AUTOSAR XML (schema 4-2-2)
package /VectorAutosarExplorerGeneratedObjects/SYSTEM
  system System
package /VectorAutosarExplorerGeneratedObjects/Induction_Training_BB
  can cluster Induction_Training_BB: baudrate=500000, protocol-name=CAN, speed=250000
    can physical channel CAR_BackBone: comm-connectors=[Connector_eJAD_AC_ECU_5f730b4d60fd8937, Connector_Car_Network_695cc9c2051648f8]
      frame AmbTempOutCar: id 0x1A7, from Car_Network, to eJAD_AC_ECU, frame-length=12, can-addressing-mode=STANDARD, can-frame-tx-behavior=CAN-20
        pdu AmbTempOutCar_PDU: length=8
          signal AmbTempOutCar_PDU_Signal: start 0, 12 bit, little-endian, system signal AmbTempOutCar_PDU_Signal_e8e9817b538522da, data-type-policy=OVERRIDE, base-type=New_BaseType, compu {phys=raw*0.1-127.5 for raw -127.5..126.5}, to eJAD_AC_ECU
      frame AmbTempInCar: id 0x242, from Car_Network, to eJAD_AC_ECU, frame-length=8, can-addressing-mode=STANDARD, can-frame-tx-behavior=CAN-20
        pdu AmbTempInCar_PDU: length=8
          signal AmbTempInCar_PDU_Signal: start 10, 12 bit, little-endian, system signal AmbTempInCar_PDU_Signal_d38db15a12d99ae0, data-type-policy=OVERRIDE, base-type=New_BaseType_1, compu {phys=raw*0.1-127.5 for raw -127.5..126.5}, to eJAD_AC_ECU
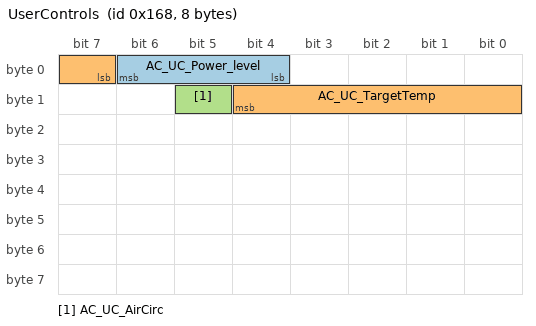
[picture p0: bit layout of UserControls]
      frame UserControls: id 0x168, from Car_Network, to eJAD_AC_ECU, frame-length=8, can-addressing-mode=STANDARD, can-frame-tx-behavior=CAN-20
        pdu UserControls_PDU: length=8
          signal AC_UC_Power_level: start 4, 3 bit, little-endian, system signal AC_UC_Power_level_a94e1a11ca90d4ce, data-type-policy=OVERRIDE, base-type=New_BaseType_2, compu {0=AC_UNIT_OFF, 1..4=AC_UNIT_PL1..AC_UNIT_PL4, 5=AC_UNIT_MAX}, to eJAD_AC_ECU
          signal AC_UC_TargetTemp: start 7, 6 bit, little-endian, system signal AC_UC_TargetTemp_525caf780043ccd2, data-type-policy=OVERRIDE, base-type=New_BaseType_2, compu {phys=raw for raw 18..33}, to eJAD_AC_ECU
          signal AC_UC_AirCirc: start 13, 1 bit, little-endian, system signal AC_UC_AirCirc_4982379d745170f0, data-type-policy=OVERRIDE, base-type=New_BaseType_2, compu {phys=raw for raw 0..1}, to eJAD_AC_ECU
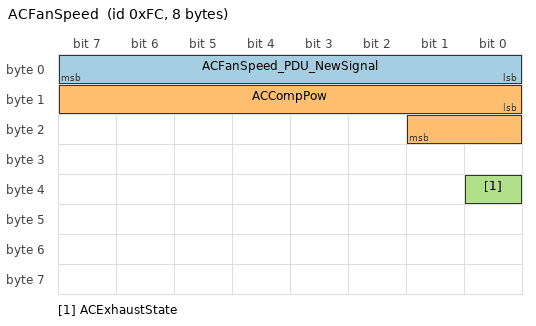
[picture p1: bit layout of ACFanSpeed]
      frame ACFanSpeed: id 0xFC, from eJAD_AC_ECU, to Car_Network, frame-length=8, can-addressing-mode=STANDARD, can-frame-tx-behavior=CAN-20
        pdu ACFanSpeed_PDU: length=8
          signal ACFanSpeed_PDU_NewSignal: start 0, 8 bit, little-endian, system signal ACFanSpeed_PDU_NewSignal_fc7b1c6d9e92d4ff, data-type-policy=OVERRIDE, base-type=New_BaseType, to Car_Network
          signal ACCompPow: start 8, 10 bit, little-endian, system signal ACCompPow_274b307919b78395, data-type-policy=OVERRIDE, base-type=New_BaseType, compu {phys=raw for raw 0..750}, to Car_Network
          signal ACExhaustState: start 32, 1 bit, little-endian, system signal ACExhaustState_7fbac8b577bd68fd, data-type-policy=OVERRIDE, base-type=New_BaseType, to Car_Network
package /VectorAutosarExplorerGeneratedObjects/ECU_INSTANCES
  ecu instance eJAD_AC_ECU: associated-com-i-pdu-group=[PduGroup_6f1441ac0ffe40b4a12c41c00adac4bd_Rx, PduGroup_b6fddf9f996e4f7a947d8b87f8da3fb2_Rx, PduGroup_df39a3b4272b424f80ca0a1ab2d3ac62_Rx, PduGroup_c82bbc8115c7464b87dc9baec7e90fcb_Tx, PduGroup_ff9273c8d3e04add9b1da927b56ab3f5_Tx], diagnostic-address=0
    can communication controller Controller_eJAD_AC_ECU_7f252cc98424769f: can-controller-attributes=can-controller-configuration={time-seg-1=15, time-seg-2=15}
    can communication controller Controller_eJAD_AC_ECU_5f3c2b4b33700a26
    can communication connector Connector_eJAD_AC_ECU_5f730b4d60fd8937: comm-controller=Controller_eJAD_AC_ECU_7f252cc98424769f
    can communication connector Connector_eJAD_AC_ECU_6d360ae10a108b45: comm-controller=Controller_eJAD_AC_ECU_5f3c2b4b33700a26
  ecu instance ExternalTester: associated-com-i-pdu-group=PduGroup_5b4b45473c864a7aaadf3ae2082b22b3_Rx, diagnostic-address=0
    can communication controller Controller_ExternalTester_4f982107dc28de72
    can communication connector Connector_ExternalTester_6d8a6f9d0db8a12c: comm-controller=Controller_ExternalTester_4f982107dc28de72
  ecu instance Car_Network: associated-com-i-pdu-group=[PduGroup_8e237c9982f64dca92b43b8216140bb0_Tx, PduGroup_b78d3610b2834c2f94fc1fb22db2b92b_Tx, PduGroup_a5c65429b06144e7a14e06515dbb2266_Tx, PduGroup_878513473f814259a7fd8765f5a041dc_Rx], diagnostic-address=0
    can communication controller Controller_Car_Network_f7f423b8d4eb37f4
    can communication connector Connector_Car_Network_695cc9c2051648f8: comm-controller=Controller_Car_Network_f7f423b8d4eb37f4
package /VectorAutosarExplorerGeneratedObjects/FRAME
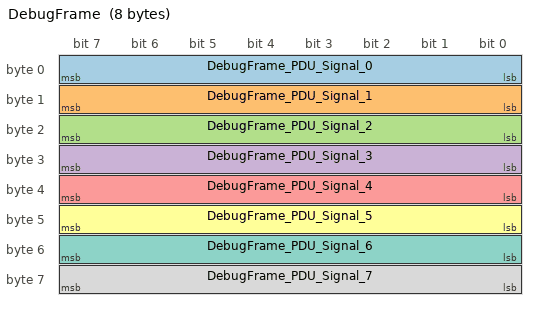
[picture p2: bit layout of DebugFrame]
  can frame DebugFrame: frame-length=8
    pdu to frame mapping PduToFrameMapping_aeacf570964c49d9: packing-byte-order=little-endian, pdu=DebugFrame_PDU, start-position=0
package /VectorAutosarExplorerGeneratedObjects/PDUS
  pdu DebugFrame_PDU: length=8
    signal DebugFrame_PDU_Signal_0: start 0, 8 bit, little-endian, system signal DebugFrame_PDU_Signal_e5542f4b3f7b291a, data-type-policy=OVERRIDE, base-type=New_BaseType
    signal DebugFrame_PDU_Signal_1: start 8, 8 bit, little-endian, system signal DebugFrame_PDU_Signal_1_12279d49a53c901b, data-type-policy=OVERRIDE, base-type=New_BaseType
    signal DebugFrame_PDU_Signal_2: start 16, 8 bit, little-endian, system signal DebugFrame_PDU_Signal_2_8561e72dcdf17113, data-type-policy=OVERRIDE, base-type=New_BaseType
    signal DebugFrame_PDU_Signal_3: start 24, 8 bit, little-endian, system signal DebugFrame_PDU_Signal_3_81eb2576279cd454, data-type-policy=OVERRIDE, base-type=New_BaseType
    signal DebugFrame_PDU_Signal_4: start 32, 8 bit, little-endian, system signal DebugFrame_PDU_Signal_4_0cc91ab208154770, data-type-policy=OVERRIDE, base-type=New_BaseType
    signal DebugFrame_PDU_Signal_5: start 40, 8 bit, little-endian, system signal DebugFrame_PDU_Signal_5_933b26994c02f7a8, data-type-policy=OVERRIDE, base-type=New_BaseType
    signal DebugFrame_PDU_Signal_6: start 48, 8 bit, little-endian, system signal DebugFrame_PDU_Signal_6_09c967ce66403780, data-type-policy=OVERRIDE, base-type=New_BaseType
    signal DebugFrame_PDU_Signal_7: start 56, 8 bit, little-endian, system signal DebugFrame_PDU_Signal_7_32774b3af81110d8, data-type-policy=OVERRIDE, base-type=New_BaseType
package /VectorAutosarExplorerGeneratedObjects/BASE_TYPES
  base type New_BaseType: base-type-size=16, base-type-encoding=NONE
  base type New_BaseType_1: base-type-size=16, base-type-encoding=NONE
  base type New_BaseType_2: base-type-size=16, base-type-encoding=NONE
package /VectorAutosarExplorerGeneratedObjects/PDU_GROUP
  10 x i signal i pdu group:
    PduGroup_8e237c9982f64dca92b43b8216140bb0_Tx: communication-direction=OUT
    PduGroup_6f1441ac0ffe40b4a12c41c00adac4bd_Rx: communication-direction=IN
    PduGroup_b78d3610b2834c2f94fc1fb22db2b92b_Tx: communication-direction=OUT
    PduGroup_b6fddf9f996e4f7a947d8b87f8da3fb2_Rx: communication-direction=IN
    PduGroup_a5c65429b06144e7a14e06515dbb2266_Tx: communication-direction=OUT
    PduGroup_df39a3b4272b424f80ca0a1ab2d3ac62_Rx: communication-direction=IN
    PduGroup_c82bbc8115c7464b87dc9baec7e90fcb_Tx: communication-direction=OUT
    PduGroup_878513473f814259a7fd8765f5a041dc_Rx: communication-direction=IN
    PduGroup_ff9273c8d3e04add9b1da927b56ab3f5_Tx: communication-direction=OUT
    PduGroup_5b4b45473c864a7aaadf3ae2082b22b3_Rx: communication-direction=IN
